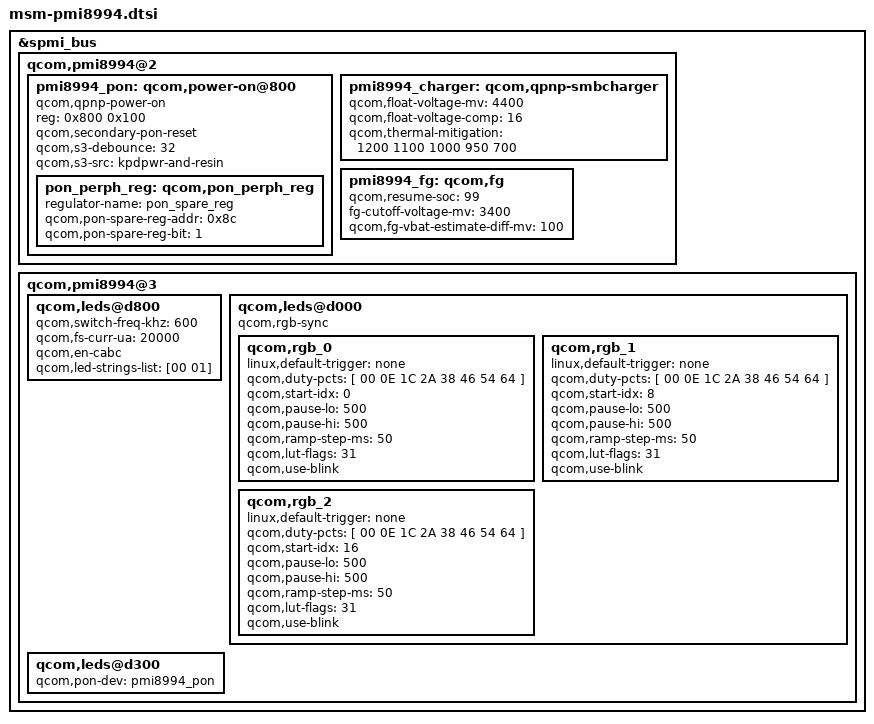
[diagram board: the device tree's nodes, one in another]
/* Copyright (c) 2014-2015, The Linux Foundation. All rights reserved.
 * Copyright (C) 2016 XiaoMi, Inc.
 * Modified by Ketut Putu Kumajaya, 2016
 *
 * This program is free software; you can redistribute it and/or modify
 * it under the terms of the GNU General Public License version 2 and
 * only version 2 as published by the Free Software Foundation.
 *
 * This program is distributed in the hope that it will be useful,
 * but WITHOUT ANY WARRANTY; without even the implied warranty of
 * MERCHANTABILITY or FITNESS FOR A PARTICULAR PURPOSE.  See the
 * GNU General Public License for more details.
 */

#include "../msm-pmi8994.dtsi"

&spmi_bus {
	qcom,pmi8994@2 {
		pmi8994_pon: qcom,power-on@800 {
			compatible = "qcom,qpnp-power-on";
			reg = <0x800 0x100>;
			qcom,secondary-pon-reset;
			qcom,s3-debounce = <32>;
			qcom,s3-src = "kpdpwr-and-resin";
			pon_perph_reg: qcom,pon_perph_reg {
				regulator-name = "pon_spare_reg";
				qcom,pon-spare-reg-addr = <0x8c>;
				qcom,pon-spare-reg-bit = <1>;
			};
		};

		pmi8994_charger: qcom,qpnp-smbcharger {
			qcom,float-voltage-mv = <4400>;
			qcom,float-voltage-comp = <16>;
			qcom,thermal-mitigation = <1200 1100 1000 950 700>;
		};

		pmi8994_fg: qcom,fg {
			qcom,resume-soc = <99>;
			status = "okay";
			fg-cutoff-voltage-mv = <3400>;
			qcom,fg-vbat-estimate-diff-mv = <100>;
		};
	};

	qcom,pmi8994@3 {
		qcom,leds@d800 {
			qcom,switch-freq-khz = <600>;
			qcom,fs-curr-ua = <20000>;
			qcom,en-cabc;
			qcom,led-strings-list = [00 01];
		};

		qcom,leds@d000 {
			qcom,rgb-sync;

			qcom,rgb_0 {
				linux,default-trigger = "none";
				qcom,duty-pcts = [ 00 0E 1C 2A 38 46 54 64 ];
				qcom,start-idx = <0>;
				qcom,pause-lo = <500>;
				qcom,pause-hi = <500>;
				qcom,ramp-step-ms = <50>;
				qcom,lut-flags = <31>; /* loop, ramp up, reverse, pause hi, pause lo */
				qcom,use-blink;
			};

			qcom,rgb_1 {
				linux,default-trigger = "none";
				qcom,duty-pcts = [ 00 0E 1C 2A 38 46 54 64 ];
				qcom,start-idx = <8>;
				qcom,pause-lo = <500>;
				qcom,pause-hi = <500>;
				qcom,ramp-step-ms = <50>;
				qcom,lut-flags = <31>; /* loop, ramp up, reverse, pause hi, pause lo */
				qcom,use-blink;
			};

			qcom,rgb_2 {
				linux,default-trigger = "none";
				qcom,duty-pcts = [ 00 0E 1C 2A 38 46 54 64 ];
				qcom,start-idx = <16>;
				qcom,pause-lo = <500>;
				qcom,pause-hi = <500>;
				qcom,ramp-step-ms = <50>;
				qcom,lut-flags = <31>; /* loop, ramp up, reverse, pause hi, pause lo */
				qcom,use-blink;
			};
		};

		qcom,leds@d300 {
			qcom,pon-dev = <&pmi8994_pon>;
		};
	};
};
